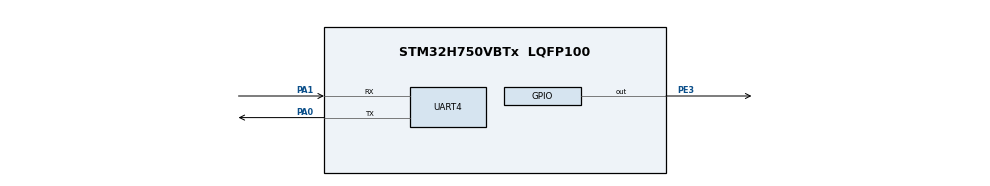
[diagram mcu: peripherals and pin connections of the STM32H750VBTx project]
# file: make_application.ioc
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Mcu.Family=STM32H7
Mcu.Name=STM32H750VBTx
Mcu.Package=LQFP100
NVIC.PriorityGroup=NVIC_PRIORITYGROUP_4
PA0.Mode=Asynchronous
PA0.Signal=UART4_TX
PA1.Mode=Asynchronous
PA1.Signal=UART4_RX
PE3.Signal=GPIO_Output
PH0-OSC_IN\ (PH0).Mode=HSE-External-Oscillator
PH0-OSC_IN\ (PH0).Signal=RCC_OSC_IN
PH1-OSC_OUT\ (PH1).Mode=HSE-External-Oscillator
PH1-OSC_OUT\ (PH1).Signal=RCC_OSC_OUT
ProjectManager.HeapSize=0x200
ProjectManager.StackSize=0x400
ProjectManager.TargetToolchain=Makefile
RCC.ADCFreq_Value=200000000
RCC.APB1Freq_Value=120000000
RCC.APB2Freq_Value=120000000
RCC.APB3Freq_Value=120000000
RCC.APB4Freq_Value=120000000
RCC.CortexFreq_Value=480000000
RCC.D1PPRE=RCC_APB3_DIV2
RCC.D2PPRE1=RCC_APB1_DIV2
RCC.D2PPRE2=RCC_APB2_DIV2
RCC.D3PPRE=RCC_APB4_DIV2
RCC.DIVM1=5
RCC.DIVM2=8
RCC.DIVM3=5
RCC.DIVN1=192
RCC.DIVN2=128
RCC.DIVN3=128
RCC.HCLKFreq_Value=240000000
RCC.HPRE=RCC_HCLK_DIV2
RCC.PLLSourceVirtual=RCC_PLLSOURCE_HSE
RCC.SYSCLKFreq_VALUE=480000000
RCC.SYSCLKSource=RCC_SYSCLKSOURCE_PLLCLK
RCC.USBFreq_Value=480000000
board=custom

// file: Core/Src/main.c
/* USER CODE BEGIN Header */
/**
  ******************************************************************************
  * @file           : main.c
  * @brief          : Main program body
  ******************************************************************************
  * @attention
  *
  * Copyright (c) 2022 STMicroelectronics.
  * All rights reserved.
  *
  * This software is licensed under terms that can be found in the LICENSE file
  * in the root directory of this software component.
  * If no LICENSE file comes with this software, it is provided AS-IS.
  *
  ******************************************************************************
  */
/* USER CODE END Header */
#include "main.h"

UART_HandleTypeDef huart4;

void SystemClock_Config(void);
static void MX_GPIO_Init(void);
static void MX_UART4_Init(void);
/* USER CODE BEGIN PFP */
uint8_t debug[] = {"Yuki.\r\n"};
/* USER CODE END PFP */

int main(void)
{
	/* USER CODE BEGIN 1 */
	for(uint8_t i = 0; i < 8; i++)
	{
		NVIC->ICER[i]=0xFFFFFFFF;
		NVIC->ICPR[i]=0xFFFFFFFF;
	}
	SCB->VTOR = QSPI_BASE;
	__enable_irq();
	__set_PRIMASK(0);
	/* USER CODE END 1 */

	/* MCU Configuration--------------------------------------------------------*/

	/* Reset of all peripherals, Initializes the Flash interface and the Systick. */
	HAL_Init();

	/* Configure the system clock */
	SystemClock_Config();

	/* Initialize all configured peripherals */
	MX_GPIO_Init();
	MX_UART4_Init();

	/* Infinite loop */
	/* USER CODE BEGIN WHILE */
	HAL_UART_Transmit(&huart4, debug, sizeof(debug), 100);
	while (1)
	{
		/* USER CODE END WHILE */

		/* USER CODE BEGIN 3 */
		HAL_GPIO_TogglePin(GPIOE, GPIO_PIN_3);
		HAL_Delay(250);
		HAL_GPIO_TogglePin(GPIOE, GPIO_PIN_3);
		HAL_Delay(250);
	}
	/* USER CODE END 3 */
}

void SystemClock_Config(void)
{
	RCC_OscInitTypeDef RCC_OscInitStruct = {0};
	RCC_ClkInitTypeDef RCC_ClkInitStruct = {0};

	/** Supply configuration update enable
	 */
	HAL_PWREx_ConfigSupply(PWR_LDO_SUPPLY);

	/** Configure the main internal regulator output voltage
	 */
	__HAL_PWR_VOLTAGESCALING_CONFIG(PWR_REGULATOR_VOLTAGE_SCALE0);

	while(!__HAL_PWR_GET_FLAG(PWR_FLAG_VOSRDY)) {}

	/** Initializes the RCC Oscillators according to the specified parameters
	 * in the RCC_OscInitTypeDef structure.
	 */
	RCC_OscInitStruct.OscillatorType = RCC_OSCILLATORTYPE_HSE;
	RCC_OscInitStruct.HSEState = RCC_HSE_ON;
	RCC_OscInitStruct.PLL.PLLState = RCC_PLL_ON;
	RCC_OscInitStruct.PLL.PLLSource = RCC_PLLSOURCE_HSE;
	RCC_OscInitStruct.PLL.PLLM = 5;
	RCC_OscInitStruct.PLL.PLLN = 192;
	RCC_OscInitStruct.PLL.PLLP = 2;
	RCC_OscInitStruct.PLL.PLLQ = 2;
	RCC_OscInitStruct.PLL.PLLR = 2;
	RCC_OscInitStruct.PLL.PLLRGE = RCC_PLL1VCIRANGE_2;
	RCC_OscInitStruct.PLL.PLLVCOSEL = RCC_PLL1VCOWIDE;
	RCC_OscInitStruct.PLL.PLLFRACN = 0;
	if (HAL_RCC_OscConfig(&RCC_OscInitStruct) != HAL_OK)
	{
		Error_Handler();
	}

	/** Initializes the CPU, AHB and APB buses clocks
	 */
	RCC_ClkInitStruct.ClockType = RCC_CLOCKTYPE_HCLK|RCC_CLOCKTYPE_SYSCLK
								|RCC_CLOCKTYPE_PCLK1|RCC_CLOCKTYPE_PCLK2
								|RCC_CLOCKTYPE_D3PCLK1|RCC_CLOCKTYPE_D1PCLK1;
	RCC_ClkInitStruct.SYSCLKSource = RCC_SYSCLKSOURCE_PLLCLK;
	RCC_ClkInitStruct.SYSCLKDivider = RCC_SYSCLK_DIV1;
	RCC_ClkInitStruct.AHBCLKDivider = RCC_HCLK_DIV2;
	RCC_ClkInitStruct.APB3CLKDivider = RCC_APB3_DIV2;
	RCC_ClkInitStruct.APB1CLKDivider = RCC_APB1_DIV2;
	RCC_ClkInitStruct.APB2CLKDivider = RCC_APB2_DIV2;
	RCC_ClkInitStruct.APB4CLKDivider = RCC_APB4_DIV2;

	if (HAL_RCC_ClockConfig(&RCC_ClkInitStruct, FLASH_LATENCY_4) != HAL_OK)
	{
		Error_Handler();
	}
}

static void MX_UART4_Init(void)
{

	huart4.Instance = UART4;
	huart4.Init.BaudRate = 115200;
	huart4.Init.WordLength = UART_WORDLENGTH_8B;
	huart4.Init.StopBits = UART_STOPBITS_1;
	huart4.Init.Parity = UART_PARITY_NONE;
	huart4.Init.Mode = UART_MODE_TX_RX;
	huart4.Init.HwFlowCtl = UART_HWCONTROL_NONE;
	huart4.Init.OverSampling = UART_OVERSAMPLING_16;
	huart4.Init.OneBitSampling = UART_ONE_BIT_SAMPLE_DISABLE;
	huart4.Init.ClockPrescaler = UART_PRESCALER_DIV1;
	huart4.AdvancedInit.AdvFeatureInit = UART_ADVFEATURE_NO_INIT;
	if (HAL_UART_Init(&huart4) != HAL_OK)
	{
		Error_Handler();
	}
	if (HAL_UARTEx_SetTxFifoThreshold(&huart4, UART_TXFIFO_THRESHOLD_1_8) != HAL_OK)
	{
		Error_Handler();
	}
	if (HAL_UARTEx_SetRxFifoThreshold(&huart4, UART_RXFIFO_THRESHOLD_1_8) != HAL_OK)
	{
		Error_Handler();
	}
	if (HAL_UARTEx_DisableFifoMode(&huart4) != HAL_OK)
	{
		Error_Handler();
	}

}

static void MX_GPIO_Init(void)
{
	GPIO_InitTypeDef GPIO_InitStruct = {0};

	/* GPIO Ports Clock Enable */
	__HAL_RCC_GPIOE_CLK_ENABLE();
	__HAL_RCC_GPIOH_CLK_ENABLE();
	__HAL_RCC_GPIOA_CLK_ENABLE();

	/*Configure GPIO pin Output Level */
	HAL_GPIO_WritePin(GPIOE, GPIO_PIN_3, GPIO_PIN_RESET);

	/*Configure GPIO pin : PE3 */
	GPIO_InitStruct.Pin = GPIO_PIN_3;
	GPIO_InitStruct.Mode = GPIO_MODE_OUTPUT_PP;
	GPIO_InitStruct.Pull = GPIO_NOPULL;
	GPIO_InitStruct.Speed = GPIO_SPEED_FREQ_LOW;
	HAL_GPIO_Init(GPIOE, &GPIO_InitStruct);

}

void Error_Handler(void)
{
	__disable_irq();
	while (1)
	{
	}
}
